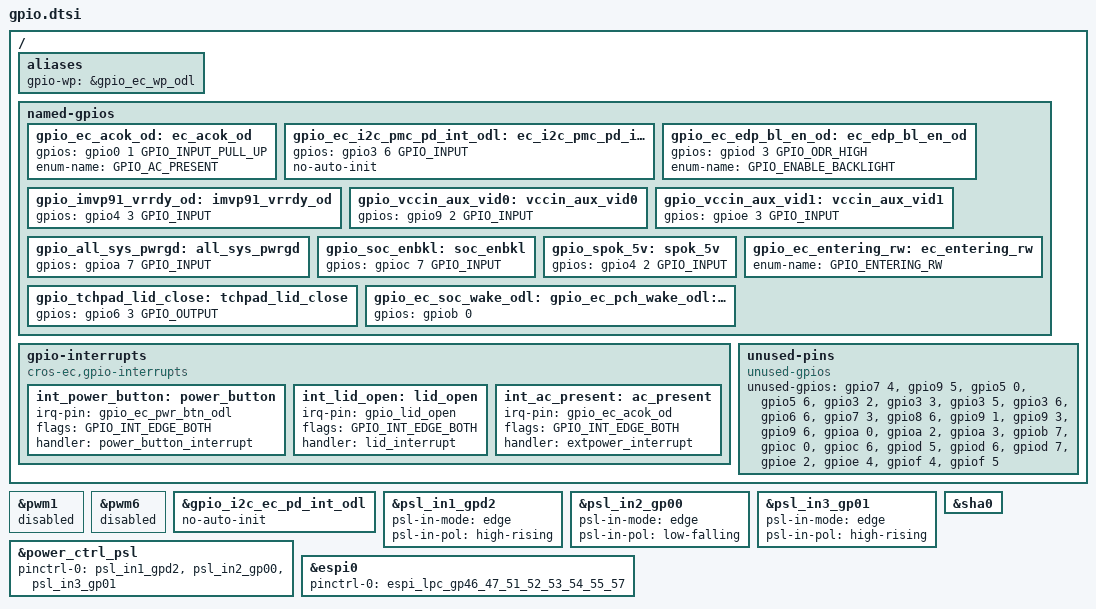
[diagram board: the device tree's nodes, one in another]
/* Copyright 2025 The ChromiumOS Authors
 * Use of this source code is governed by a BSD-style license that can be
 * found in the LICENSE file.
 */

 #include <cros/integrated_fwid.dtsi>

 / {

	aliases {
		gpio-wp = &gpio_ec_wp_odl;
	};

	named-gpios {
		/delete-node/ acok_od;
		/delete-node/ amp_mute_l;
		/delete-node/ charger_vap_otg_en;
		/delete-node/ ec_pmc_pd_int_odl;
		/delete-node/ gsc_ec_pwr_btn_odl;
		/delete-node/ ec_tris_l;
		/delete-node/ en_kb_bl;
		/delete-node/ en_pp5000_pen_x;
		/delete-node/ gsc_ec_pwr_btn_odl;
		/delete-node/ imvp91_vrrdy_r_od;
		/delete-node/ pdc_rst;
		/delete-node/ pen_detect_odl;
		/delete-node/ vccin_aux_r_vid0;
		/delete-node/ vccin_aux_r_vid1;
		/delete-node/ all_sys_pwrgd;
		/delete-node/ volup_btn_odl;
		/delete-node/ voldn_btn_odl;
		/delete-node/ pg_pp5000_z1_od;
		/delete-node/ acc_int_l;
		/delete-node/ imu_int_l;
		/delete-node/ tablet_mode_l;

		gpio_ec_acok_od: ec_acok_od {
			gpios = <&gpio0 1 GPIO_INPUT_PULL_UP>;
			enum-name = "GPIO_AC_PRESENT";
		};
		gpio_ec_i2c_pmc_pd_int_odl: ec_i2c_pmc_pd_int_odl {
			gpios = <&gpio3 6 GPIO_INPUT>;
		};
		gpio_ec_edp_bl_en_od: ec_edp_bl_en_od {
			gpios = <&gpiod 3 GPIO_ODR_HIGH>;
			enum-name = "GPIO_ENABLE_BACKLIGHT";
		};
		gpio_imvp91_vrrdy_od: imvp91_vrrdy_od {
			gpios = <&gpio4 3 GPIO_INPUT>;
		};
		gpio_vccin_aux_vid0: vccin_aux_vid0 {
			gpios = <&gpio9 2 GPIO_INPUT>;
		};
		gpio_vccin_aux_vid1: vccin_aux_vid1 {
			gpios = <&gpioe 3 GPIO_INPUT>;
		};
		gpio_all_sys_pwrgd: all_sys_pwrgd {
			gpios = <&gpioa 7 GPIO_INPUT>;
		};
		gpio_soc_enbkl: soc_enbkl {
			gpios = <&gpioc 7 GPIO_INPUT>;
		};
		gpio_spok_5v: spok_5v {
			gpios = <&gpio4 2 GPIO_INPUT>;
		};
		gpio_tchpad_lid_close: tchpad_lid_close {
			gpios = <&gpio6 3 GPIO_OUTPUT>;
		};
		gpio_ec_soc_wake_odl: ec_soc_wake_odl {
			gpios = <&gpiob 0 (GPIO_OUTPUT | GPIO_OPEN_DRAIN | GPIO_OUTPUT_INIT_LOW)>;
		};
		/* The legacy system code requires GPIO_ENTERING_RW symbol */
		gpio_ec_entering_rw: ec_entering_rw {
			enum-name = "GPIO_ENTERING_RW";
		};
	};
	gpio-interrupts {
		compatible = "cros-ec,gpio-interrupts";

		int_power_button: power_button {
			irq-pin = <&gpio_ec_pwr_btn_odl>;
			flags = <GPIO_INT_EDGE_BOTH>;
			handler = "power_button_interrupt";
		};
		int_lid_open: lid_open {
			irq-pin = <&gpio_lid_open>;
			flags = <GPIO_INT_EDGE_BOTH>;
			handler = "lid_interrupt";
		};
		int_ac_present: ac_present {
			irq-pin = <&gpio_ec_acok_od>;
			flags = <GPIO_INT_EDGE_BOTH>;
			handler = "extpower_interrupt";
		};
	};
	unused-pins {
		compatible = "unused-gpios";
		unused-gpios =
		    <&gpio7 4 0>,
			<&gpio9 5 0>,
			<&gpio5 0 0>,
			<&gpio5 6 0>,
			<&gpio3 2 0>,
			<&gpio3 3 0>,
			<&gpio3 5 0>,
			<&gpio3 6 0>,
			<&gpio6 6 0>,
			<&gpio7 3 0>,
			<&gpio8 6 0>,
			<&gpio9 1 0>,
			<&gpio9 3 0>,
			<&gpio9 6 0>,
			<&gpioa 0 0>,
			<&gpioa 2 0>,
			<&gpioa 3 0>,
			<&gpiob 7 0>,
			<&gpioc 0 0>,
			<&gpioc 6 0>,
			<&gpiod 5 0>,
			<&gpiod 6 0>,
			<&gpiod 7 0>,
			<&gpioe 2 0>,
			<&gpioe 4 0>,
			<&gpiof 4 0>,
			<&gpiof 5 0>;
	};
};
&pwm1 {
	status = "disabled";
};

&pwm6 {
	status = "disabled";
};

/* These GPIOS are initialized by the PDC driver */
&gpio_i2c_ec_pd_int_odl {
	no-auto-init;
};
&gpio_ec_i2c_pmc_pd_int_odl {
	no-auto-init;
};

/* Power switch logic input pads */
/* LID_OPEN_OD */
&psl_in1_gpd2 {
	psl-in-mode = "edge";
	psl-in-pol = "high-rising";
};

/* EC_PWR_BTN_ODL */
&psl_in2_gp00 {
	psl-in-mode = "edge";
	psl-in-pol = "low-falling";
};

/* ACOK_EC_OD */
&psl_in3_gp01 {
	psl-in-mode = "edge";
	psl-in-pol = "high-rising";
};

/* Power domain device controlled by PSL (Power Switch Logic) IO pads */
&power_ctrl_psl {
	status = "okay";
	pinctrl-names = "sleep";
	pinctrl-0 = <&psl_in1_gpd2 &psl_in2_gp00 &psl_in3_gp01>;
};

/* The eSPI shim requires this GPIO nodelabel */
gpio_ec_pch_wake_odl: &gpio_ec_soc_wake_odl {
};

/* host interface */
&espi0 {
	status = "okay";
	pinctrl-0 = <&espi_lpc_gp46_47_51_52_53_54_55_57>;
	pinctrl-names = "default";
};

&sha0 {
	status = "okay";
};
